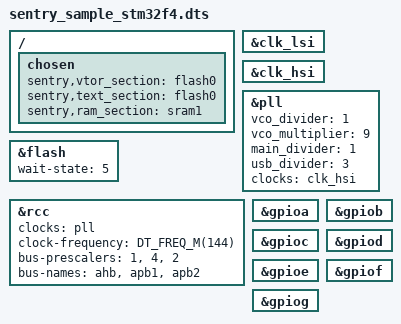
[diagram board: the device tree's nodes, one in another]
/*
 * Copyright (c) 2023,Ledger SAS
 *
 * SPDX-License-Identifier: Apache-2.0
 */

/dts-v1/;

#include <st/f4/stm32f429Xi.dtsi>

/{
	chosen {
		sentry,vtor_section = <&flash0>;
		sentry,text_section = <&flash0>;
		sentry,ram_section = <&sram1>;
	};

};

&clk_lsi {
	status = "okay";
};

&clk_hsi {
	status = "okay";
};

&pll {
	vco_divider = <1>;
	vco_multiplier = <9>;
	main_divider = <1>;
	usb_divider = <3>;
	clocks = <&clk_hsi>;
	status = "okay";
};

&flash {
	wait-state = <5>; /* According to voltage supply and sysclock */
	status = "okay";
};

&rcc {
	clocks = <&pll>;
	clock-frequency = <DT_FREQ_M(144)>;
	bus-prescalers = <1>, <4>, <2>;
	bus-names = "ahb", "apb1", "apb2";
	status = "okay";
};

&gpioa {
	status = "okay";
};

&gpiob {
	status = "okay";
};

&gpioc {
	status = "okay";
};

&gpiod {
	status = "okay";
};

&gpioe {
	status = "okay";
};

&gpiof {
	status = "okay";
};

&gpiog {
	status = "okay";
};
